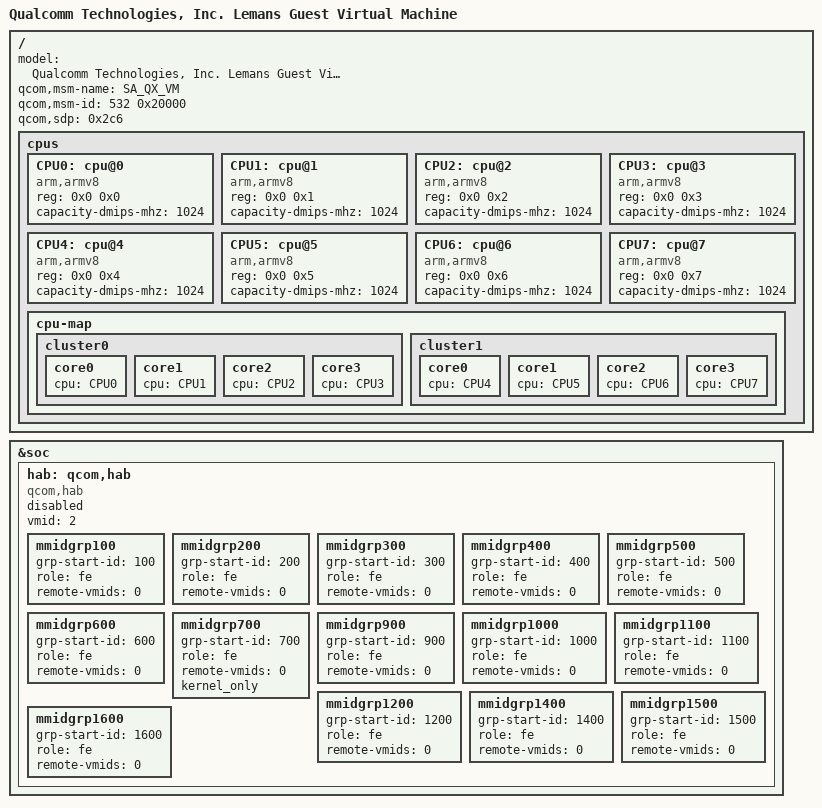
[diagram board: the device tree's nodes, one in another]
// SPDX-License-Identifier: BSD-3-Clause
/*
 * Copyright (c) Qualcomm Technologies, Inc. and/or its subsidiaries.
 */

#include "prime-quin-vm-common.dtsi"

/ {
	model = "Qualcomm Technologies, Inc. Lemans Guest Virtual Machine";
	qcom,msm-name  = "SA_QX_VM";
	qcom,msm-id = <532 0x20000>;
	qcom,sdp = <0x2c6>;

	cpus {
		#address-cells = <2>;
		#size-cells = <0>;

		CPU0: cpu@0 {
			device_type = "cpu";
			compatible = "arm,armv8";
			reg = <0x0 0x0>;
			capacity-dmips-mhz = <1024>;
		};

		CPU1: cpu@1 {
			device_type = "cpu";
			compatible = "arm,armv8";
			reg = <0x0 0x1>;
			capacity-dmips-mhz = <1024>;
		};

		CPU2: cpu@2 {
			device_type = "cpu";
			compatible = "arm,armv8";
			reg = <0x0 0x2>;
			capacity-dmips-mhz = <1024>;
		};

		CPU3: cpu@3 {
			device_type = "cpu";
			compatible = "arm,armv8";
			reg = <0x0 0x3>;
			capacity-dmips-mhz = <1024>;
		};

		CPU4: cpu@4 {
			device_type = "cpu";
			compatible = "arm,armv8";
			reg = <0x0 0x4>;
			capacity-dmips-mhz = <1024>;
		};

		CPU5: cpu@5 {
			device_type = "cpu";
			compatible = "arm,armv8";
			reg = <0x0 0x5>;
			capacity-dmips-mhz = <1024>;
		};

		CPU6: cpu@6 {
			device_type = "cpu";
			compatible = "arm,armv8";
			reg = <0x0 0x6>;
			capacity-dmips-mhz = <1024>;
		};

		CPU7: cpu@7 {
			device_type = "cpu";
			compatible = "arm,armv8";
			reg = <0x0 0x7>;
			capacity-dmips-mhz = <1024>;
		};

		cpu-map {
			cluster0 {
				core0 {
					cpu = <&CPU0>;
				};

				core1 {
					cpu = <&CPU1>;
				};

				core2 {
					cpu = <&CPU2>;
				};

				core3 {
					cpu = <&CPU3>;
				};
			};

			cluster1 {
				core0 {
					cpu = <&CPU4>;
				};

				core1 {
					cpu = <&CPU5>;
				};

				core2 {
					cpu = <&CPU6>;
				};

				core3 {
					cpu = <&CPU7>;
				};
			};
		};
	};
};

&soc {
	hab: qcom,hab {
		compatible = "qcom,hab";
		vmid = <2>;
		status = "disabled";

		mmidgrp100 {
			grp-start-id = <100>;
			role = "fe";
			remote-vmids = <0>;
		};

		mmidgrp200 {
			grp-start-id = <200>;
			role = "fe";
			remote-vmids = <0>;
		};

		mmidgrp300 {
			grp-start-id = <300>;
			role = "fe";
			remote-vmids = <0>;
		};

		mmidgrp400 {
			grp-start-id = <400>;
			role = "fe";
			remote-vmids = <0>;
		};

		mmidgrp500 {
			grp-start-id = <500>;
			role = "fe";
			remote-vmids = <0>;
		};

		mmidgrp600 {
			grp-start-id = <600>;
			role = "fe";
			remote-vmids = <0>;
		};

		mmidgrp700 {
			grp-start-id = <700>;
			role = "fe";
			remote-vmids = <0>;
			kernel_only;
		};

		mmidgrp900 {
			grp-start-id = <900>;
			role = "fe";
			remote-vmids = <0>;
		};

		mmidgrp1000 {
			grp-start-id = <1000>;
			role = "fe";
			remote-vmids = <0>;
		};

		mmidgrp1100 {
			grp-start-id = <1100>;
			role = "fe";
			remote-vmids = <0>;
		};

		mmidgrp1200 {
			grp-start-id = <1200>;
			role = "fe";
			remote-vmids = <0>;
		};

		mmidgrp1400 {
			grp-start-id = <1400>;
			role = "fe";
			remote-vmids = <0>;
		};

		mmidgrp1500 {
			grp-start-id = <1500>;
			role = "fe";
			remote-vmids = <0>;
		};

		mmidgrp1600 {
			grp-start-id = <1600>;
			role = "fe";
			remote-vmids = <0>;
		};
	};
};
